AUTOSAR XML (schema 4-3-0)
package /App_WDT
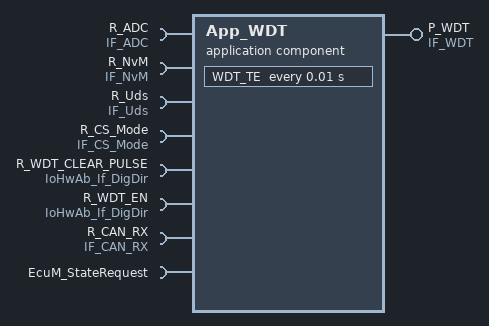
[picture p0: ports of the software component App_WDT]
  application sw component type App_WDT
    6 x require port:
      R_ADC: nonqueued-receiver-com-spec=ADC_STR, required-interface=IF_ADC
      R_NvM: nonqueued-receiver-com-spec=NvM_STR, required-interface=IF_NvM
      R_Uds: nonqueued-receiver-com-spec=Uds_STR, required-interface=IF_Uds
      R_CS_Mode: required-com-specs=[ModeInit, NvMInit, ApplicationInit], required-interface=IF_CS_Mode
      R_WDT_CLEAR_PULSE: client-com-spec=WriteDirect, required-interface=IoHwAb_If_DigDir
      R_WDT_EN: client-com-spec=WriteDirect, required-interface=IoHwAb_If_DigDir
    provide port P_WDT: nonqueued-sender-com-spec=WDT_STR, provided-interface=IF_WDT
    require port R_CAN_RX: nonqueued-receiver-com-spec=CAN_RX_STR, required-interface=IF_CAN_RX
    require port EcuM_StateRequest: client-com-spec=RequestReset, required-interface=EcuM_StateRequest
    behavior InternalBehavior: data-type-mapping=DataTypeMappingSet_WPC
      timing event TE_WDT_TE: start-on-event=WDT_TE, period=0.01
      runnable WDT_TE: symbol=WDT_TE_Runnable
        data-receive-point-by-arguments:
          4 x access, all with scope=COMMUNICATION-INTER-ECU:
            DRPBA_WDT_TE_R_BCAN_RX_BCAN_RX_STR: accessed-variable=R_CAN_RX.CAN_RX_STR
            DRPBA_WDT_TE_R_Uds_Uds_STR: accessed-variable=R_Uds.Uds_STR
            DRPBA_WDT_TE_R_NvM_NvM_STR: accessed-variable=R_NvM.NvM_STR
            DRPBA_WDT_TE_R_ADC_ADC_STR: accessed-variable=R_ADC.ADC_STR
        data-send-points:
          access DSP_WDT_TE_P_WDT_WDT_STR: accessed-variable=P_WDT.WDT_STR, scope=COMMUNICATION-INTER-ECU
        6 x sync call:
          SSCP_WDT_TE_R_CS_Mode_ApplicationInit: operation=R_CS_Mode.ApplicationInit
          SSCP_WDT_TE_R_CS_Mode_ModeInit: operation=R_CS_Mode.ModeInit
          SSCP_WDT_TE_R_CS_Mode_NvMInit: operation=R_CS_Mode.NvMInit
          SSCP_WDT_TE_R_WDT_CLEAR_PULSE_WriteDirect: operation=R_WDT_CLEAR_PULSE.WriteDirect
          SSCP_WDT_TE_R_WDT_EN_WriteDirect: operation=R_WDT_EN.WriteDirect
          SSCP_WDT_TE_EcuM_StateRequest_RequestReset: operation=EcuM_StateRequest.RequestReset
  sender receiver interface IF_WDT  # NFC SWC Output
    data WDT_STR: type=IDT_WDT_STR
